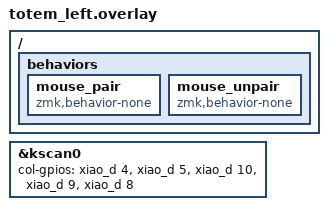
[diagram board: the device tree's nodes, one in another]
/*
 * Copyright (c) 2022 The ZMK Contributors
 *
 * SPDX-License-Identifier: MIT
 */

#include "totem.dtsi"

&kscan0 {
    col-gpios
        = <&xiao_d 4 GPIO_ACTIVE_HIGH>
        , <&xiao_d 5 GPIO_ACTIVE_HIGH>
        , <&xiao_d 10 GPIO_ACTIVE_HIGH>
        , <&xiao_d 9 GPIO_ACTIVE_HIGH>
        , <&xiao_d 8 GPIO_ACTIVE_HIGH>
        ;
};

/* totem.keymap is shared by every build and binds &mouse_pair / &mouse_unpair
 * (Navigation layer). The real behaviors live in totem_dongle.overlay; these
 * stubs only make the labels resolve (zmk-ble-mouse-host README, "Split
 * keyboards"). Inert: pressing them does nothing without the dongle. */
/ {
    behaviors {
        mouse_pair: mouse_pair {
            compatible = "zmk,behavior-none";
            #binding-cells = <0>;
        };

        mouse_unpair: mouse_unpair {
            compatible = "zmk,behavior-none";
            #binding-cells = <0>;
        };
    };
};
